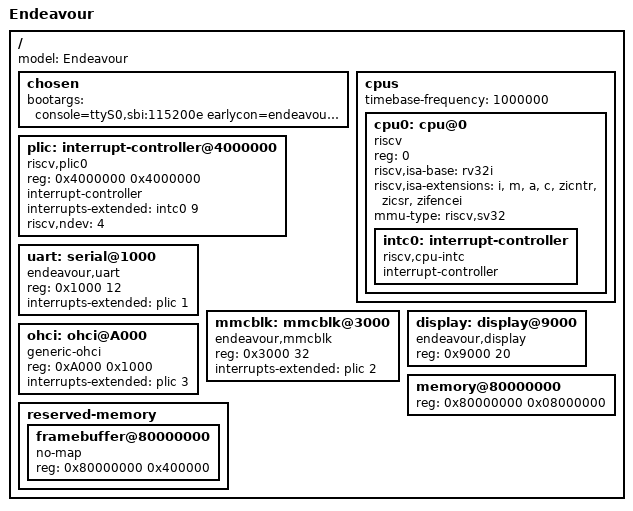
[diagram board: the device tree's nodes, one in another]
// SPDX-License-Identifier: GPL-3.0
/dts-v1/;

/ {
  #address-cells = <1>;
  #size-cells = <1>;
  model = "Endeavour";

  chosen {
    //bootargs = "console=ttyS0,sbi:115200e earlycon=endeavour_sbi debug root=/dev/ram";
    //bootargs = "console=ttyS0,sbi:115200e earlycon=endeavour_sbi debug root=/dev/mmcblk0p1";
    bootargs = "console=ttyS0,sbi:115200e earlycon=endeavour_sbi root=/dev/mmcblk0p1";
    //bootargs = "console=ttyS0,sbi:115200e root=/dev/ram";
    //linux,initrd-start = <0x87000000>;
    //linux,initrd-end   = <0x87400000>;
  };

  cpus {
    #address-cells = <1>;
    #size-cells = <0>;
    timebase-frequency = <1000000>;
    cpu0: cpu@0 {
      device_type = "cpu";
      reg = <0>;
      status = "okay";
      compatible = "riscv";
      riscv,isa-base = "rv32i";
      riscv,isa-extensions = "i", "m", "a", "c", "zicntr", "zicsr", "zifencei";
      mmu-type = "riscv,sv32";
      intc0: interrupt-controller {
        #interrupt-cells = <1>;
        interrupt-controller;
        compatible = "riscv,cpu-intc";
      };
    };
  };

  plic: interrupt-controller@4000000 {
    compatible = "riscv,plic0";
    reg = <0x4000000 0x4000000>;
    #address-cells = <0>;
    #size-cells = <0>;
    #interrupt-cells = <1>;
    interrupt-controller;
    interrupts-extended = <&intc0 9>;
    riscv,ndev = <4>;
  };

  uart: serial@1000 {
    compatible = "endeavour,uart";
    reg = <0x1000 12>;
    interrupts-extended = <&plic 1>;
  };

  /*audio: audio@2000 {
    compatible = "endeavour,audio";
    reg = <0x2000 8>;
  };*/

  mmcblk: mmcblk@3000 {
    compatible = "endeavour,mmcblk";
    reg = <0x3000 32>;
    interrupts-extended = <&plic 2>;
  };

  display: display@9000 {
    compatible = "endeavour,display";
    reg = <0x9000 20>;
  };

  ohci: ohci@A000 {
    compatible = "generic-ohci";
    reg = <0xA000 0x1000>;
    status = "okay";
    interrupts-extended = <&plic 3>;
  };

  memory@80000000 {
    device_type = "memory";
    reg = <0x80000000 0x08000000>;
  };

  reserved-memory {
    #address-cells = <1>;
    #size-cells = <1>;
    ranges;
    framebuffer@80000000 {
      no-map;
      reg = <0x80000000 0x400000>;
    };
  };

};
